# CY8C5868AXI_LP035 register map
File version: 0.1
CY8C58LP
Registers are 8-bit, read-write, no defined reset value unless marked. A register's access mark holds for its fields unless they carry their own. Offsets are from the block's base; lines under a group give offsets from that group; [hi:lo] are bit positions; {n}, {i} and the like mark numbered series; 'fields as' and 'values as' point back to an identical list; <NAME> marks a mode.

## Memory map
0x00000000 Comparator_Counter
0x00000000 Vertical_Sync_Counter
0x00000000 Timer
0x00000000 PWM
0x00000000 Composite_Sync_Counter
0x00000000 PWM_Steering

## Comparator_Counter
Base 0x00000000
0x40006405 Comparator_Counter_COUNTER — UDB.A0 - Current Counter Value
0x40006425 Comparator_Counter_PERIOD — UDB.D0 - Assigned Period
0x40006435 Comparator_Counter_COMPARE — UDB.D1 - Assigned Compare Value
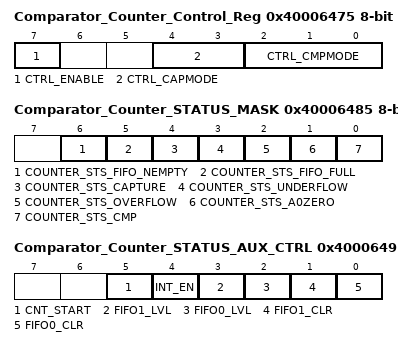
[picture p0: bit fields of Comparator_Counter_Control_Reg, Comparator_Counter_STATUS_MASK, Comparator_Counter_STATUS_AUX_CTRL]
0x40006475 Comparator_Counter_Control_Reg — UDB Control Register - Assigned Control Register Value
  [7] CTRL_ENABLE — Enable Counter
  [4:3] CTRL_CAPMODE — Capture mode
  [2:0] CTRL_CMPMODE — Compare mode
0x40006485 Comparator_Counter_STATUS_MASK — UDB Status bits Interrupt Mask Enable Register
  [6] COUNTER_STS_FIFO_NEMPTY — FIFO Not Empty Status
  [5] COUNTER_STS_FIFO_FULL — FIFO Full Status
  [4] COUNTER_STS_CAPTURE — Capture Status
  [3] COUNTER_STS_UNDERFLOW — Underflow status
  [2] COUNTER_STS_OVERFLOW — Overflow status
  [1] COUNTER_STS_A0ZERO — A0 Zero ouput status
  [0] COUNTER_STS_CMP — Compare output status
0x40006495 Comparator_Counter_STATUS_AUX_CTRL — UDB Auxilliary Control Register
  [5] CNT_START — FIFO0 clear
    0=E_CNT_START0 (Disable counter); 1=E_CNT_START1 (Enable counter)
  [4] INT_EN
    0=E_INT_EN0 (Interrupt disabled); 1=E_INT_EN1 (Interrupt enabled)
  [3] FIFO1_LVL — FIFO level
    0=E_FIFO_LVL_0 (FIFO LVL: input mode: FIFO not full; output mode: FIFO not empty); 1=E_FIFO_LVL_1 (FIFO LVL: input mode: FIFO at least 1/2 empty; output mode: FIFO at least 1/2 full)
  [2] FIFO0_LVL — FIFO level
    values as FIFO1_LVL
  [1] FIFO1_CLR — FIFO1 clear
    0=E_FIFO_CLR_0 (Normal FIFO operation); 1=E_FIFO_CLR_1 (Clear FIFO state)
  [0] FIFO0_CLR — FIFO0 clear
    values as FIFO1_CLR

## Vertical_Sync_Counter
Base 0x00000000
0x40006406 Vertical_Sync_Counter_COUNTER — UDB.A0 - Current Counter Value
0x40006426 Vertical_Sync_Counter_PERIOD — UDB.D0 - Assigned Period
0x40006436 Vertical_Sync_Counter_COMPARE — UDB.D1 - Assigned Compare Value
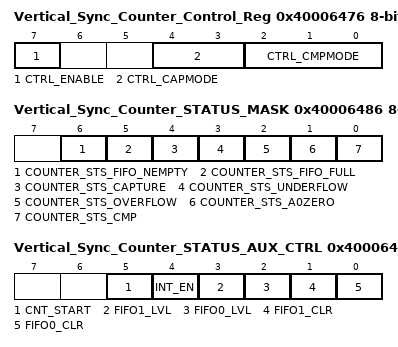
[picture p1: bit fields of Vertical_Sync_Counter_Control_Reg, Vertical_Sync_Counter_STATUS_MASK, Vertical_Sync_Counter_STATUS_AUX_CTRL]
0x40006476 Vertical_Sync_Counter_Control_Reg — UDB Control Register - Assigned Control Register Value
  [7] CTRL_ENABLE — Enable Counter
  [4:3] CTRL_CAPMODE — Capture mode
  [2:0] CTRL_CMPMODE — Compare mode
0x40006486 Vertical_Sync_Counter_STATUS_MASK — UDB Status bits Interrupt Mask Enable Register
  [6] COUNTER_STS_FIFO_NEMPTY — FIFO Not Empty Status
  [5] COUNTER_STS_FIFO_FULL — FIFO Full Status
  [4] COUNTER_STS_CAPTURE — Capture Status
  [3] COUNTER_STS_UNDERFLOW — Underflow status
  [2] COUNTER_STS_OVERFLOW — Overflow status
  [1] COUNTER_STS_A0ZERO — A0 Zero ouput status
  [0] COUNTER_STS_CMP — Compare output status
0x40006496 Vertical_Sync_Counter_STATUS_AUX_CTRL — UDB Auxilliary Control Register
  [5] CNT_START — FIFO0 clear
    0=E_CNT_START0 (Disable counter); 1=E_CNT_START1 (Enable counter)
  [4] INT_EN
    0=E_INT_EN0 (Interrupt disabled); 1=E_INT_EN1 (Interrupt enabled)
  [3] FIFO1_LVL — FIFO level
    0=E_FIFO_LVL_0 (FIFO LVL: input mode: FIFO not full; output mode: FIFO not empty); 1=E_FIFO_LVL_1 (FIFO LVL: input mode: FIFO at least 1/2 empty; output mode: FIFO at least 1/2 full)
  [2] FIFO0_LVL — FIFO level
    values as FIFO1_LVL
  [1] FIFO1_CLR — FIFO1 clear
    0=E_FIFO_CLR_0 (Normal FIFO operation); 1=E_FIFO_CLR_1 (Clear FIFO state)
  [0] FIFO0_CLR — FIFO0 clear
    values as FIFO1_CLR

## Timer
Base 0x00000000
0x40006402 Timer_COUNTER 16-bit — UDB.A0 - Current Down Counter Value
0x40006422 Timer_PERIOD 16-bit — UDB.D0 - Assigned Period
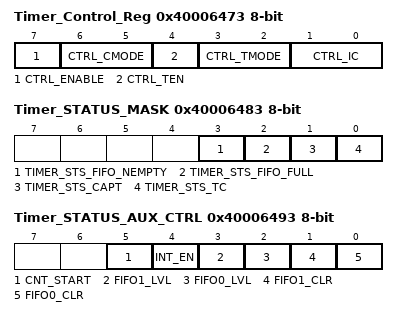
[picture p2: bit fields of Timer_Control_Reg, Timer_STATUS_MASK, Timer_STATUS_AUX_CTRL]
0x40006473 Timer_Control_Reg — UDB Control Register - Assigned Control Register Value
  [7] CTRL_ENABLE — Enable the Timer
  [6:5] CTRL_CMODE — Capture Mode
  [4] CTRL_TEN — Trigger Enable Bit
  [3:2] CTRL_TMODE — Trigger Mode
  [1:0] CTRL_IC — Interrupt Count
0x40006483 Timer_STATUS_MASK — UDB Status bits Interrupt Mask Enable Register
  [3] TIMER_STS_FIFO_NEMPTY ro — FIFO Empty status
  [2] TIMER_STS_FIFO_FULL ro — FIFO Full Status
  [1] TIMER_STS_CAPT ro — Enables the Interrupt on Capture
  [0] TIMER_STS_TC ro — Enables the Interrupt on TC
0x40006493 Timer_STATUS_AUX_CTRL — UDB Auxilliary Control Register
  [5] CNT_START — FIFO0 clear
    0=E_CNT_START0 (Disable counter); 1=E_CNT_START1 (Enable counter)
  [4] INT_EN
    0=E_INT_EN0 (Interrupt disabled); 1=E_INT_EN1 (Interrupt enabled)
  [3] FIFO1_LVL — FIFO level
    0=E_FIFO_LVL_0 (FIFO LVL: input mode: FIFO not full; output mode: FIFO not empty); 1=E_FIFO_LVL_1 (FIFO LVL: input mode: FIFO at least 1/2 empty; output mode: FIFO at least 1/2 full)
  [2] FIFO0_LVL — FIFO level
    values as FIFO1_LVL
  [1] FIFO1_CLR — FIFO1 clear
    0=E_FIFO_CLR_0 (Normal FIFO operation); 1=E_FIFO_CLR_1 (Clear FIFO state)
  [0] FIFO0_CLR — FIFO0 clear
    values as FIFO1_CLR
